# WKUP_GTC0_GTC_CFG0 register map
Vendor: Texas Instruments
Peripheral module from a debugger description file (folder J722S).
Registers are 32-bit, read-only, reset 0x61800209 unless marked. A register's access mark holds for its fields unless they carry their own. Offsets are as the file gives them; lines under a group give offsets from that group; [hi:lo] are bit positions; {n}, {i} and the like mark numbered series; 'fields as' and 'values as' point back to an identical list; <NAME> marks a mode.

## WKUP_GTC0_GTC_CFG0
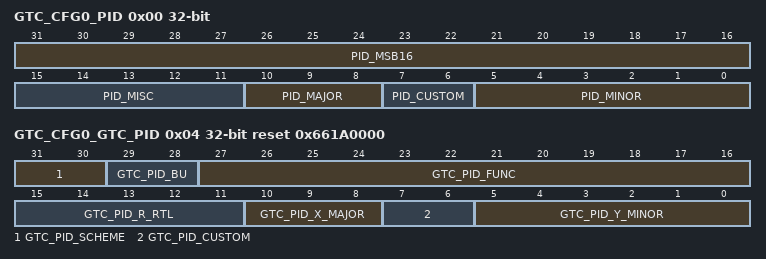
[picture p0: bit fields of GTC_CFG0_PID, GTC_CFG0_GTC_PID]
0x00 GTC_CFG0_PID
  [31:16] PID_MSB16, [15:11] PID_MISC, [10:8] PID_MAJOR, [7:6] PID_CUSTOM, [5:0] PID_MINOR
0x04 GTC_CFG0_GTC_PID reset 0x661A0000
  [31:30] GTC_PID_SCHEME — PID follows new scheme
  [29:28] GTC_PID_BU — Business unit - Processors
  [27:16] GTC_PID_FUNC — Module functional identifier - GTC module
  [15:11] GTC_PID_R_RTL — RTL revision number - actual value determined by RTL
  [10:8] GTC_PID_X_MAJOR — Major revision number - actual value determined by RTL
  [7:6] GTC_PID_CUSTOM — Custom revision number - actual value determined by RTL
  [5:0] GTC_PID_Y_MINOR — Minor revision number - actual value determined by RTL
0x08 GTC_CFG0_PUSHEVT rw reset 0x0
  [5:0] PUSHEVT_EXPBIT_SEL — Selects which bit [63:0] of the System Counter value is exported on the push_evt output. This field controls the 64:1 mux that drives the push_evt output.
